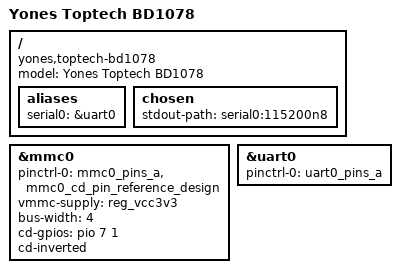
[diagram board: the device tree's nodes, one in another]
// SPDX-License-Identifier: GPL-2.0+ OR X11
/*
 * Copyright 2015 Hans de Goede <hdegoede@redhat.com>
 *
 * Minimal dts file for the Yones Toptech BD1078 for u-boot only
 */

/dts-v1/;
#include "sun7i-a20.dtsi"
#include "sunxi-common-regulators.dtsi"
#include <dt-bindings/gpio/gpio.h>
#include <dt-bindings/pinctrl/sun4i-a10.h>

/ {
	model = "Yones Toptech BD1078";
	compatible = "yones,toptech-bd1078", "allwinner,sun7i-a20";

	aliases {
		serial0 = &uart0;
	};

	chosen {
		stdout-path = "serial0:115200n8";
	};
};

&mmc0 {
	pinctrl-names = "default";
	pinctrl-0 = <&mmc0_pins_a>, <&mmc0_cd_pin_reference_design>;
	vmmc-supply = <&reg_vcc3v3>;
	bus-width = <4>;
	cd-gpios = <&pio 7 1 GPIO_ACTIVE_HIGH>; /* PH1 */
	cd-inverted;
	status = "okay";
};

&uart0 {
	pinctrl-names = "default";
	pinctrl-0 = <&uart0_pins_a>;
	status = "okay";
};
